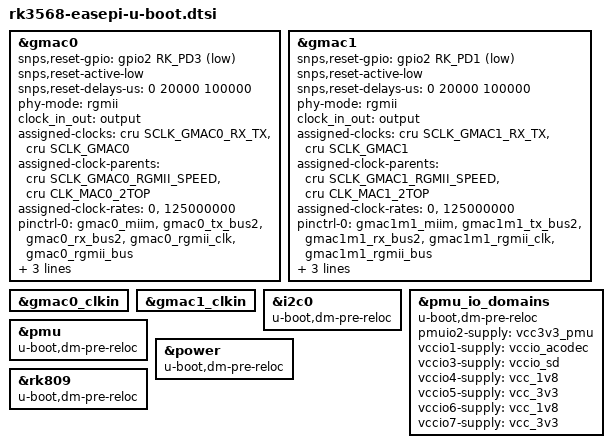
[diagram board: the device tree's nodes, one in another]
/*
 * SPDX-License-Identifier:     GPL-2.0+
 *
 * (C) Copyright 2020 Rockchip Electronics Co., Ltd
 */

#include "rk3568-u-boot.dtsi"

&gmac0 {
	snps,reset-gpio = <&gpio2 RK_PD3 GPIO_ACTIVE_LOW>;
	snps,reset-active-low;
	/* Reset time is 20ms, 100ms for rtl8211f */
	snps,reset-delays-us = <0 20000 100000>;

	phy-mode = "rgmii";
	clock_in_out = "output";

	assigned-clocks = <&cru SCLK_GMAC0_RX_TX>, <&cru SCLK_GMAC0>;
	assigned-clock-parents = <&cru SCLK_GMAC0_RGMII_SPEED>, <&cru CLK_MAC0_2TOP>;
	assigned-clock-rates = <0>, <125000000>;

	pinctrl-names = "default";
	pinctrl-0 = <&gmac0_miim
		     &gmac0_tx_bus2
		     &gmac0_rx_bus2
		     &gmac0_rgmii_clk
		     &gmac0_rgmii_bus>;

	tx_delay = <0x35>;
	rx_delay = <0x2b>;

	phy-handle = <&rgmii_phy0>;
	status = "okay";
};

&gmac1 {
	snps,reset-gpio = <&gpio2 RK_PD1 GPIO_ACTIVE_LOW>;
	snps,reset-active-low;
	/* Reset time is 20ms, 100ms for rtl8211f */
	snps,reset-delays-us = <0 20000 100000>;

	phy-mode = "rgmii";
	clock_in_out = "output";

	assigned-clocks = <&cru SCLK_GMAC1_RX_TX>, <&cru SCLK_GMAC1>;
	assigned-clock-parents = <&cru SCLK_GMAC1_RGMII_SPEED>, <&cru CLK_MAC1_2TOP>;
	assigned-clock-rates = <0>, <125000000>;

	pinctrl-names = "default";
	pinctrl-0 = <&gmac1m1_miim
		     &gmac1m1_tx_bus2
		     &gmac1m1_rx_bus2
		     &gmac1m1_rgmii_clk
		     &gmac1m1_rgmii_bus>;

	tx_delay = <0x42>;
	rx_delay = <0x27>;

	phy-handle = <&rgmii_phy1>;
	status = "okay";
};

&gmac0_clkin {
	status = "okay";
};

&gmac1_clkin {
	status = "okay";
};

&i2c0 {
	u-boot,dm-pre-reloc;
	status = "okay";
};

&pmu_io_domains {
	u-boot,dm-pre-reloc;
	status = "okay";
	pmuio2-supply = <&vcc3v3_pmu>;
	vccio1-supply = <&vccio_acodec>;
	vccio3-supply = <&vccio_sd>;
	vccio4-supply = <&vcc_1v8>;
	vccio5-supply = <&vcc_3v3>;
	vccio6-supply = <&vcc_1v8>;
	vccio7-supply = <&vcc_3v3>;
};

&pmu {
	u-boot,dm-pre-reloc;
	status = "okay";
};

&power {
	u-boot,dm-pre-reloc;
	status = "okay";
};

&rk809 {
	u-boot,dm-pre-reloc;
	status = "okay";
};
